# CY8C5888LTI_LP097 register map
File version: 0.1
CY8C58LP
Registers are 8-bit, read-write, no defined reset value unless marked. A register's access mark holds for its fields unless they carry their own. Offsets are from the block's base; lines under a group give offsets from that group; [hi:lo] are bit positions; {n}, {i} and the like mark numbered series; 'fields as' and 'values as' point back to an identical list; <NAME> marks a mode.

## Memory map
0x00000000 UART_Slave — UART
0x00000000 SPI_Slave

## UART_Slave — UART
Base 0x00000000
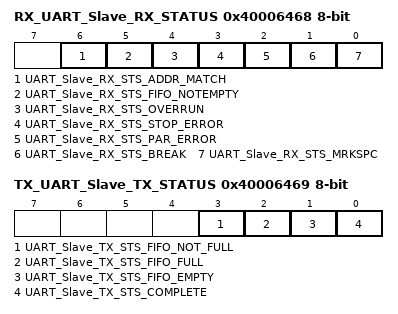
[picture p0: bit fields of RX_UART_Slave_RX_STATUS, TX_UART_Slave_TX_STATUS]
0x40006468 RX_UART_Slave_RX_STATUS — RX status register
  [6] UART_Slave_RX_STS_ADDR_MATCH ro, [5] UART_Slave_RX_STS_FIFO_NOTEMPTY ro, [4] UART_Slave_RX_STS_OVERRUN ro, [3] UART_Slave_RX_STS_STOP_ERROR ro, [2] UART_Slave_RX_STS_PAR_ERROR ro, [1] UART_Slave_RX_STS_BREAK ro, [0] UART_Slave_RX_STS_MRKSPC ro
0x40006469 TX_UART_Slave_TX_STATUS — TX status register
  [3] UART_Slave_TX_STS_FIFO_NOT_FULL ro, [2] UART_Slave_TX_STS_FIFO_FULL ro, [1] UART_Slave_TX_STS_FIFO_EMPTY ro, [0] UART_Slave_TX_STS_COMPLETE ro
0x40006528 RX_UART_Slave_RX_ADDRESS1 — RX Address1 Register
0x40006538 RX_UART_Slave_RX_ADDRESS2 — RX Address2 Register
0x40006548 RX_UART_Slave_RX_DATA — RX Data Register
0x4000654A TX_UART_Slave_TX_DATA — TX Data Register

## SPI_Slave
Base 0x00000000
0x40006408 SPI_Slave_RX_DATA — SPIS RX Data
0x40006408 SPI_Slave_TX_DATA — SPIS TX Data
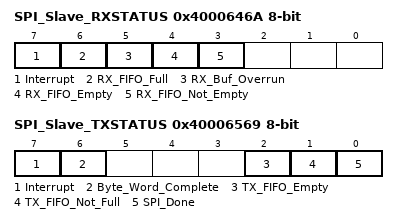
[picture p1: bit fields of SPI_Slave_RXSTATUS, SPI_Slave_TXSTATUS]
0x4000646A SPI_Slave_RXSTATUS — SPIS RX Status Register
  [7] Interrupt ro — Set when interrupt occurs
  [6] RX_FIFO_Full ro — Set when the RX Data FIFO is full
  [5] RX_Buf_Overrun ro — Set when RX Data has overrun the 4 byte/word FIFO without being moved to the RX buffer cmemory array (if one exists)
  [4] RX_FIFO_Empty ro — Set when the RX Data FIFO is empty
  [3] RX_FIFO_Not_Empty ro — Set when the RX Data FIFO is not empty. That is, at least one byte/word is in the RX FIFO
0x40006569 SPI_Slave_TXSTATUS — SPIS TX Status Register
  [7] Interrupt ro — Set when interrupt occurs
  [6] Byte_Word_Complete ro — Set when a byte/word transmit has completed
  [2] TX_FIFO_Empty ro — Set when the TX Data FIFO is empty
  [1] TX_FIFO_Not_Full ro — Set when the TX Data FIFO is not full
  [0] SPI_Done ro — Set when all of the data in the transmit FIFO has been sent. Set when Byte/Word Complete has been set and TX Data FIFO is empty
